# LPC845 register map
Vendor: nxp.com; File version: 1.0
CPU: CM0PLUS r0p0, little endian, no MPU, no FPU, VTOR, 2 interrupt priority bits
Registers are 32-bit, read-write, reset 0x0 unless marked. A register's access mark holds for its fields unless they carry their own. Offsets are from the block's base; [hi:lo] are bit positions; {n}, {i} and the like mark numbered series.

## CAPT — LPC84x Capacitive Touch
Base 0x40060000
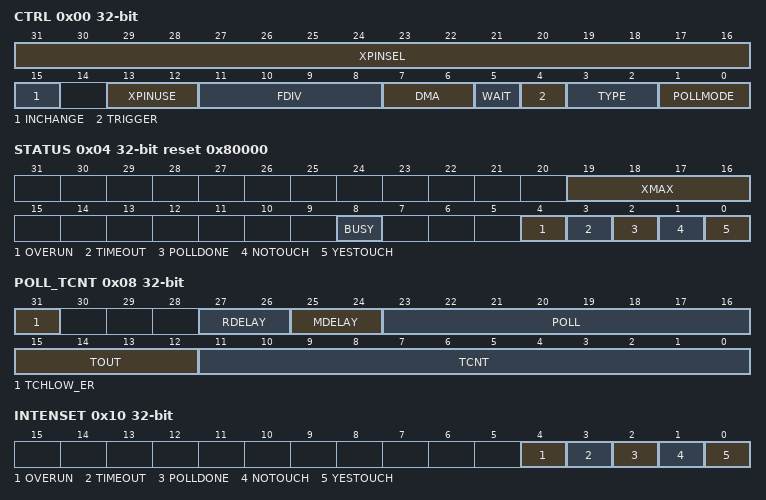
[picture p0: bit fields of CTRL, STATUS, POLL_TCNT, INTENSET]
0x00 CTRL — Configuration and control to setup the functional clock, the rules, and the pin selections and rules.
  [31:16] XPINSEL — Selects which of the X pins are to be used within the allowed pins - see XMAX in STATUS. The X pins are mapped via the IOCON (as are the YH and YL pins) to physical pads. So, this only selects which are to be used as the X half of the touch element. Note: when polling, these are "walked" (active) one at a time. When using POLLNOW, the 1 or more selected are used at the same time. Likewise, when in low-power mode, they are used at the same time (or small groups). X pads not selected by XPINSEL are kept at High-Z if they are connected to a pad. This allows using controlled sets for touch detection based on context.
  [15] INCHANGE ro — If 1, do not attempt to write to this register again. This means the last change has not been propagated. This can only happen after changing POLLMODE and DMA. Worse case time would be based on divided FCLK.
  [13:12] XPINUSE — Controls how X pins selected in XPINSEL are used when not active in the current polling round.
    0=NORMAL_MDOE (Normal mode. Each inactive X pin is Hi-Z.); 1=GROUND_MDOE (Ground mode. Each inactive X pin is Low)
  [11:8] FDIV — Functional clock divider, or 0 if no divide. The term "clocks" in this spec then refer to divided clocks. For a 12MHz input (e.g. FRO 12MHz), this would normally be set to generate a 4MHz output (so, 2). For a 1MHz input, it should be 0. Note for internal use: this does not produce a 50/50 duty cycle when non even divide.
    0=No divide; {v}=/{v+1} (v=1..5); {v}=/(FDIV+1) (v=7..15)
  [7:6] DMA — If not 0, will use the DMA to read out touch events from TOUCH register. The values are shown below. This may be changed while active.
    0=No DMA. Application will use ISRs to read out data; 1=Trigger DMA on Touch events; 2=Trigger DMA on both Touch and No-Touch events; 3=Trigger DMA on both plus Timeout
  [5] WAIT — If 0, the block will continue its X based measurements, even if the TOUCH register has not been read (and so could OVERRUN). If 1, it will wait until read when a touch (TOUCH's ISTOUCH bit is set) before starting the next. This should not normally be needed.
  [4] TRIGGER — This selects what is being used as the trigger
    0=USES_YH_GPIO (Uses YH GPIO. This is not normally used except in Low-power mode. But, it can be used with POLLNOW to baseline that measurement.); 1=ACMP (ACMP (if fitted). This assumes the ACMP state is fed in asynchronously and it will sample.)
  [3:2] TYPE — Selects type of Touch arrangement to use and so how to handle XPINSEL bits
    0=Normal - all X elements are treated as normal, such as buttons and sliders; 1=3x3 grid using NXP Complementary measurements. The 1st 9 Xs are assumed to be the 3x3 grid. After that would be normal X elements. This will also allow 3x1 and 3x2 Note: Only possible if XMAX in STATUS is >=8; 2=5 Sensors interleaved to act as 3x3 touch area using NXP Complementary measurements. 1st 5 Xs used for this, all remaining are treated as normal. Note that if 16 X pins allowed, the 16th will not be usable when TYPE=1. (use TYPE=0 and select 1 smaller than 15 ( and any others from 1 smaller than 5 on up in XPINSEL).; 3=9 Sensors interleaved to act as 5x5 touch area using NXP Complementary measurements. 1st 9 Xs used for this, all remaining are treated as normal. Note: Only possible if XMAX in STATUS is >=8
  [1:0] POLLMODE — Mode of operation. May only change from 0 to another value. So, if 2 or 3, must be changed to 0 1st. Any attempt to go from non-0 to non-0 will result in 0 anyway.
    0=NONE (None, inactive. Poll and time counters are turned off. Writing this will reset state and stop any collection in progress. Note: this has no effect on STATUS - those must be cleared manually.); 1=POLL_NOW (Poll now - forces a manual poll to be started immediately, using XPINSEL X pin(s) to activate in the integration loop (all pins set together). Self clears - clear is not indication it is done (see STATUS).); 2=NORMAL (Normal polling using poll delay from POLL_TCNT register. This will start with the poll delay (which can be 0).); 3=LOW_POWER_MODE (The CAPT block will operate in low-power mode. This means it will use GPIO as input, use combination touch measurements, and assume it is to wake the system. This will use the POLL_TCNT poll delay, and start with the delay.)
0x04 STATUS reset 0x80000 — Status from triggers and time-outs including if in a poll now. Some are used for interrupts.
  [19:16] XMAX ro — Indicates the maximum number of X pins allowed 0-relative. So, 15 means there are pins 0 to 15, or 16 total X pins. INTERNAL note: this may be setup to be written by ROM boot.
  [8] BUSY ro — In a poll now.
  [4] OVERUN write-1-clears — Is 1 if new data was collected before application read out previous ISTOUCH. No-touch (ISTOUCH==0) data will be silently overrun. Is not possible if WAIT=1.
  [3] TIMEOUT write-1-clears — Is 1 if an integration cycle ended with a timeout (should not happen).
  [2] POLLDONE write-1-clears — Is 1 if a poll or POLLNOW is complete.
  [1] NOTOUCH write-1-clears — Is 1 if a no-touch has been detected (ie. completed an integration cycle and found no-touch). This is not set when in low-power mode.
  [0] YESTOUCH write-1-clears — Is 1 if a touch has been detected, including a wakeup from low-power mode.
0x08 POLL_TCNT — This sets up the polling counter and measurement counter rules.
  [31] TCHLOW_ER — If 1, then the touch/no-touch boundary of TCNT is reversed. In a floating system (most common), the no-touch case triggers at a lower count vs. touch; this is due to touch drawing off charge. In a grounded system, the reverse is true and the touch adds to the charge and so touch is a lower count. In a system which can switch between grounded and non-grounded, the SW will check for all of the Xs looking like they have been touched and reverse the setting of this bit. This should only be changed between polls.
  [27:26] RDELAY — If not 0, this is the number of divided FCLKs to hold in Step 0 'Reset' state (draining capacitance). It is used as (1 is smaller than RDELAY), so between 2 and 8 ticks of the divided FCLK added to the 'Reset' state.
  [25:24] MDELAY — If not 0, this selects the number of divided FCLKs to wait after entry of measurement mode before deciding if has triggered. This gives the ACMP time to react to the transferred charge. It is used as 1+(1 smaller than MDELAY), , so between 2 and 8 ticks of the divided FCLK added during the measurement.
  [23:16] POLL — Poll counter in (internal) 12-bit counter wraparounds (loosely 1msec), so related to divided FCLK. This expresses time delay between measurement cycles (ie. after one set of X measurements, time before starting next). This count is used to delay before the next set of measurements. Measuring too often wastes power and does not add value since movement of fingers is relatively slow. For low power mode, this must allow for the clock being used (e.g. a 1MHz osc) so 12 bit count will be potentially much longer. That means, lowering the count to get the reasonable delay period.
  [15:12] TOUT — Time-out count expressed as 1 is smaller than TOUT, allowing for up to 12 bits. Must be less than 13. So, for example, 1 is smaller than 12=4096 counts; if TOUT=12, then if 4096 counts occur without a trigger, it is a time-out. This should be set to be large enough above TCNT to prevent timeout invalidly.
  [11:0] TCNT — Sets the threshold between touch and no-touch count. If not used, then the block will treat all events as touch or no-touch, depending whether at max or min. This is in terms of divided FCLK. If the comparator triggers it is no-touch; if bigger than TCNT counts, it is a touch event.
0x10 INTENSET — Interrupt enable
  [4] OVERUN write-1-clears — Is 1 if an overrun should interrupt.
  [3] TIMEOUT write-1-clears — Is 1 if an integration cycle ending with timeout should interrupt
  [2] POLLDONE write-1-clears — Is 1 if a poll or POLLNOW completing should interrupt
  [1] NOTOUCH write-1-clears — Is 1 if a no-touch detected should interrupt
  [0] YESTOUCH write-1-clears — Is 1 if a touch detected should interrupt. This includes wake from low-power mode.
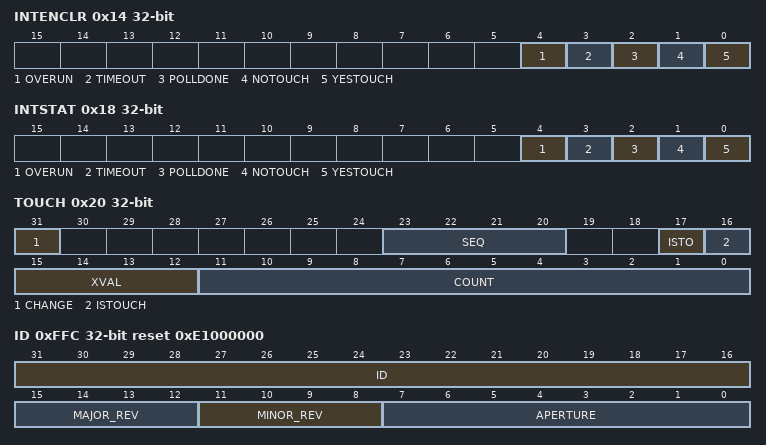
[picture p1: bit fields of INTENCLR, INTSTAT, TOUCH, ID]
0x14 INTENCLR — Interrupt enable clear
  [4] OVERUN write-1-clears — clear the overrun interrupt
  [3] TIMEOUT write-1-clears — clear the timeout interrupt
  [2] POLLDONE write-1-clears — clear the poll or POLLNOW completing interrupt
  [1] NOTOUCH write-1-clears — clear the no-touch interrupt
  [0] YESTOUCH write-1-clears — clear the touch interrupt
0x18 INTSTAT — Interrupt status (mask of STATUS and INTEN)
  [4] OVERUN ro — the status of overrun interrupt
  [3] TIMEOUT ro — the status of timeout interrupt
  [2] POLLDONE ro — the status of poll or pollnow completing interrupt
  [1] NOTOUCH ro — the status of no-touch interrrupt
  [0] YESTOUCH ro — the status of touch interrrupt
0x20 TOUCH — Last touch event (touch or no-touch) in context.
  [31] CHANGE ro — If 1, the rest of the register is 0 because the data is changing. This will only happen for 1 cycle and would never happen if using interrupts to read, unless took so long as to overrun.
  [23:20] SEQ ro — Sequence number - rolling counter of polls. Changes after all selected Xs per poll (so, 0 for 1st set of Xs, then 1 for next set, etc).
  [17] ISTO ro — 1 if is Timeout.
  [16] ISTOUCH ro — 1 if is Touch (by count) or 0 if is no-touch.
  [15:12] XVAL ro — Is the X that triggered this, or lowest X if more than one.
  [11:0] COUNT ro — Count value reached at trigger. If timeout, will be (1 bigger than TOUT)-1; e.g. if TOUT=12, then 0xFFF.
0xFFC ID ro reset 0xE1000000 — Block ID
  [31:16] ID — 1 if is Timeout.
  [15:12] MAJOR_REV — Major revision of module implementation, starting at 0. There may not be software compatibility between major revisions.
  [11:8] MINOR_REV — Minor revision of module implementation, starting at 0. Software compatibility is expected between minor revisions.
  [7:0] APERTURE — Aperture: encoded as (aperture size/4K) -1, so 0x00 is a 4 K aperture.
